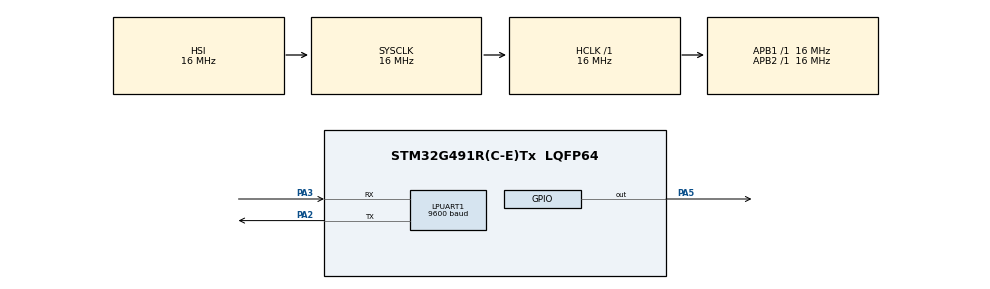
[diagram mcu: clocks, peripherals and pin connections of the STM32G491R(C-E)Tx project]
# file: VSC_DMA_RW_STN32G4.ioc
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Dma.LPUART1_RX.0.Direction=DMA_PERIPH_TO_MEMORY
Dma.LPUART1_RX.0.EventEnable=DISABLE
Dma.LPUART1_RX.0.Instance=DMA1_Channel1
Dma.LPUART1_RX.0.MemDataAlignment=DMA_MDATAALIGN_BYTE
Dma.LPUART1_RX.0.MemInc=DMA_MINC_ENABLE
Dma.LPUART1_RX.0.Mode=DMA_CIRCULAR
Dma.LPUART1_RX.0.PeriphDataAlignment=DMA_PDATAALIGN_BYTE
Dma.LPUART1_RX.0.PeriphInc=DMA_PINC_DISABLE
Dma.LPUART1_RX.0.Polarity=HAL_DMAMUX_REQ_GEN_RISING
Dma.LPUART1_RX.0.Priority=DMA_PRIORITY_LOW
Dma.LPUART1_RX.0.RequestNumber=1
Dma.LPUART1_RX.0.SignalID=NONE
Dma.LPUART1_RX.0.SyncEnable=DISABLE
Dma.LPUART1_RX.0.SyncPolarity=HAL_DMAMUX_SYNC_NO_EVENT
Dma.LPUART1_RX.0.SyncRequestNumber=1
Dma.LPUART1_RX.0.SyncSignalID=NONE
Dma.Request0=LPUART1_RX
LPUART1.BaudRate=9600
Mcu.Family=STM32G4
Mcu.Name=STM32G491R(C-E)Tx
Mcu.Package=LQFP64
NVIC.DMA1_Channel1_IRQn=true\:0\:0\:false\:false\:true\:false\:true\:true
NVIC.LPUART1_IRQn=true\:0\:0\:false\:false\:true\:true\:true\:true
NVIC.PriorityGroup=NVIC_PRIORITYGROUP_4
PA2.Mode=Asynchronous
PA2.Signal=LPUART1_TX
PA3.Mode=Asynchronous
PA3.Signal=LPUART1_RX
PA5.Signal=GPIO_Output
ProjectManager.HeapSize=0x200
ProjectManager.StackSize=0x400
ProjectManager.TargetToolchain=CMake
RCC.AHBFreq_Value=16000000
RCC.APB1Freq_Value=16000000
RCC.APB1TimFreq_Value=16000000
RCC.APB2Freq_Value=16000000
RCC.APB2TimFreq_Value=16000000
RCC.CortexFreq_Value=16000000
RCC.EXTERNAL_CLOCK_VALUE=12288000
RCC.HCLKFreq_Value=16000000
RCC.HSE_VALUE=8000000
RCC.HSI48_VALUE=48000000
RCC.HSI_VALUE=16000000
RCC.LSE_VALUE=32768
RCC.SYSCLKFreq_VALUE=16000000
RCC.VCOOutputFreq_Value=128000000
VP_SYS_VS_DBSignals.Mode=DisableDeadBatterySignals
board=custom

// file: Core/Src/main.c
/* USER CODE BEGIN Header */
/**
  ******************************************************************************
  * @file           : main.c
  * @brief          : Main program body
  ******************************************************************************
  * @attention
  *
  * Copyright (c) 2025 STMicroelectronics.
  * All rights reserved.
  *
  * This software is licensed under terms that can be found in the LICENSE file
  * in the root directory of this software component.
  * If no LICENSE file comes with this software, it is provided AS-IS.
  *
  ******************************************************************************
  */
/* USER CODE END Header */
#include "main.h"

UART_HandleTypeDef hlpuart1;
DMA_HandleTypeDef hdma_lpuart1_rx;

void SystemClock_Config(void);
static void MX_GPIO_Init(void);
static void MX_DMA_Init(void);
static void MX_LPUART1_UART_Init(void);

/* USER CODE BEGIN 0 */
uint8_t rxDmaBuf[RX_DMA_BUF_SIZE];
volatile uint16_t rxLen;
uint16_t remaining;
uint16_t received;
/* USER CODE END 0 */

int main(void)
{

  /* MCU Configuration--------------------------------------------------------*/

  /* Reset of all peripherals, Initializes the Flash interface and the Systick. */
  HAL_Init();

  /* Configure the system clock */
  SystemClock_Config();

  /* Initialize all configured peripherals */
  MX_GPIO_Init();
  MX_DMA_Init();
  MX_LPUART1_UART_Init();
  /* USER CODE BEGIN 2 */
  HAL_UART_Receive_DMA(&hlpuart1, rxDmaBuf, RX_DMA_BUF_SIZE);

/* Enable IDLE line interrupt */
  //__HAL_UART_ENABLE_IT(&hlpuart1, UART_IT_IDLE); // enable this line for IDLE interrupt

  /* USER CODE END 2 */

  /* Infinite loop */
  while (1)
  {

    /* USER CODE BEGIN 3 */
    remaining =    __HAL_DMA_GET_COUNTER(&hdma_lpuart1_rx);

    received =    RX_DMA_BUF_SIZE - remaining;

  }
  /* USER CODE END 3 */
}

void SystemClock_Config(void)
{
  RCC_OscInitTypeDef RCC_OscInitStruct = {0};
  RCC_ClkInitTypeDef RCC_ClkInitStruct = {0};

  /** Configure the main internal regulator output voltage
  */
  HAL_PWREx_ControlVoltageScaling(PWR_REGULATOR_VOLTAGE_SCALE1);

  /** Initializes the RCC Oscillators according to the specified parameters
  * in the RCC_OscInitTypeDef structure.
  */
  RCC_OscInitStruct.OscillatorType = RCC_OSCILLATORTYPE_HSI;
  RCC_OscInitStruct.HSIState = RCC_HSI_ON;
  RCC_OscInitStruct.HSICalibrationValue = RCC_HSICALIBRATION_DEFAULT;
  RCC_OscInitStruct.PLL.PLLState = RCC_PLL_NONE;
  if (HAL_RCC_OscConfig(&RCC_OscInitStruct) != HAL_OK)
  {
    Error_Handler();
  }

  /** Initializes the CPU, AHB and APB buses clocks
  */
  RCC_ClkInitStruct.ClockType = RCC_CLOCKTYPE_HCLK|RCC_CLOCKTYPE_SYSCLK
                              |RCC_CLOCKTYPE_PCLK1|RCC_CLOCKTYPE_PCLK2;
  RCC_ClkInitStruct.SYSCLKSource = RCC_SYSCLKSOURCE_HSI;
  RCC_ClkInitStruct.AHBCLKDivider = RCC_SYSCLK_DIV1;
  RCC_ClkInitStruct.APB1CLKDivider = RCC_HCLK_DIV1;
  RCC_ClkInitStruct.APB2CLKDivider = RCC_HCLK_DIV1;

  if (HAL_RCC_ClockConfig(&RCC_ClkInitStruct, FLASH_LATENCY_0) != HAL_OK)
  {
    Error_Handler();
  }
}

static void MX_LPUART1_UART_Init(void)
{

  hlpuart1.Instance = LPUART1;
  hlpuart1.Init.BaudRate = 9600;
  hlpuart1.Init.WordLength = UART_WORDLENGTH_8B;
  hlpuart1.Init.StopBits = UART_STOPBITS_1;
  hlpuart1.Init.Parity = UART_PARITY_NONE;
  hlpuart1.Init.Mode = UART_MODE_TX_RX;
  hlpuart1.Init.HwFlowCtl = UART_HWCONTROL_NONE;
  hlpuart1.Init.OneBitSampling = UART_ONE_BIT_SAMPLE_DISABLE;
  hlpuart1.Init.ClockPrescaler = UART_PRESCALER_DIV1;
  hlpuart1.AdvancedInit.AdvFeatureInit = UART_ADVFEATURE_NO_INIT;
  if (HAL_UART_Init(&hlpuart1) != HAL_OK)
  {
    Error_Handler();
  }
  if (HAL_UARTEx_SetTxFifoThreshold(&hlpuart1, UART_TXFIFO_THRESHOLD_1_8) != HAL_OK)
  {
    Error_Handler();
  }
  if (HAL_UARTEx_SetRxFifoThreshold(&hlpuart1, UART_RXFIFO_THRESHOLD_1_8) != HAL_OK)
  {
    Error_Handler();
  }
  if (HAL_UARTEx_DisableFifoMode(&hlpuart1) != HAL_OK)
  {
    Error_Handler();
  }

}

static void MX_DMA_Init(void)
{

  /* DMA controller clock enable */
  __HAL_RCC_DMAMUX1_CLK_ENABLE();
  __HAL_RCC_DMA1_CLK_ENABLE();

  /* DMA interrupt init */
  /* DMA1_Channel1_IRQn interrupt configuration */
  HAL_NVIC_SetPriority(DMA1_Channel1_IRQn, 0, 0);
  HAL_NVIC_EnableIRQ(DMA1_Channel1_IRQn);
  /* DMAMUX_OVR_IRQn interrupt configuration */
  HAL_NVIC_SetPriority(DMAMUX_OVR_IRQn, 0, 0);
  HAL_NVIC_EnableIRQ(DMAMUX_OVR_IRQn);

}

static void MX_GPIO_Init(void)
{
  GPIO_InitTypeDef GPIO_InitStruct = {0};

  /* GPIO Ports Clock Enable */
  __HAL_RCC_GPIOA_CLK_ENABLE();

  /*Configure GPIO pin Output Level */
  HAL_GPIO_WritePin(GPIOA, GPIO_PIN_5, GPIO_PIN_RESET);

  /*Configure GPIO pin : PA5 */
  GPIO_InitStruct.Pin = GPIO_PIN_5;
  GPIO_InitStruct.Mode = GPIO_MODE_OUTPUT_PP;
  GPIO_InitStruct.Pull = GPIO_NOPULL;
  GPIO_InitStruct.Speed = GPIO_SPEED_FREQ_LOW;
  HAL_GPIO_Init(GPIOA, &GPIO_InitStruct);

}

/* USER CODE BEGIN 4 */
void ProcessRxData(uint8_t *data, uint16_t len)
{
  HAL_UART_Transmit(&hlpuart1, data, len, HAL_MAX_DELAY); // echo
}

void HAL_UART_RxHalfCpltCallback(UART_HandleTypeDef *huart)
{
  if (huart->Instance == LPUART1)
  {
    // Process first half of the buffer
    ProcessRxData(rxDmaBuf, RX_DMA_BUF_SIZE / 2);
  }
}

/* USER CODE END 4 */

void Error_Handler(void)
{
  __disable_irq();
  while (1)
  {
  }
}
